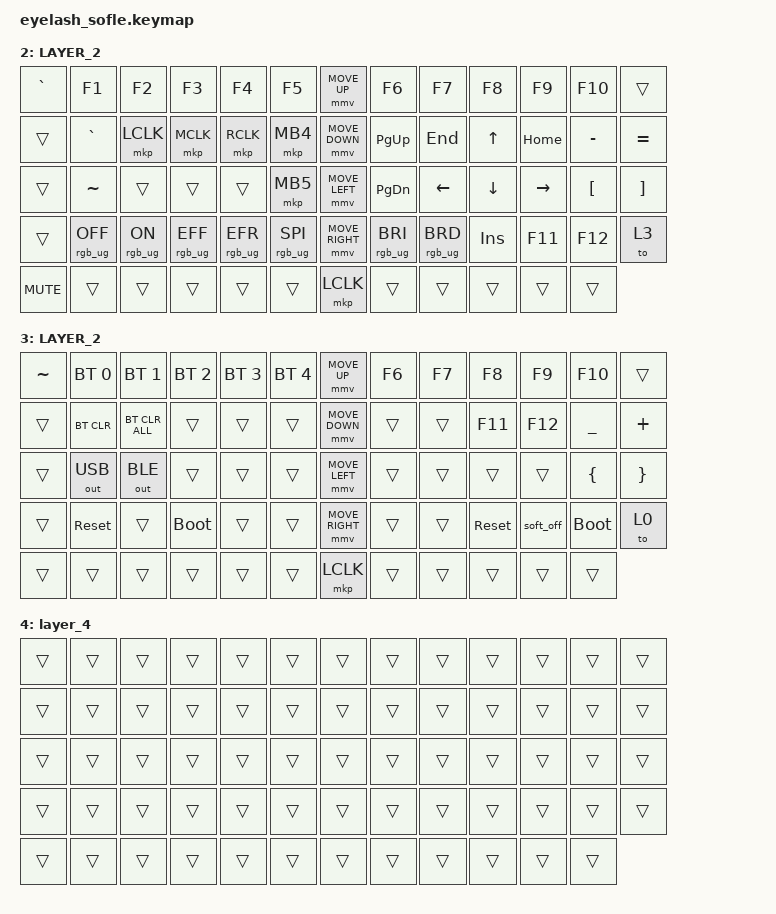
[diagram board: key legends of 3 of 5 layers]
#define ZMK_POINTING_DEFAULT_MOVE_VAL 1200  // 600
#define ZMK_POINTING_DEFAULT_SCRL_VAL 25   // 10

#include <input/processors.dtsi>
#include <zephyr/dt-bindings/input/input-event-codes.h>
#include <behaviors.dtsi>
#include <dt-bindings/zmk/bt.h>
#include <dt-bindings/zmk/ext_power.h>
#include <dt-bindings/zmk/keys.h>
#include <dt-bindings/zmk/pointing.h>
#include <dt-bindings/zmk/rgb.h>
#include <dt-bindings/zmk/outputs.h>

&mmv_input_listener { input-processors = <&zip_xy_scaler 2 1>; };

&msc_input_listener { input-processors = <&zip_scroll_scaler 2 1>; };

&msc {
    acceleration-exponent = <1>;      // 0
    time-to-max-speed-ms = <100>;       // 300
    delay-ms = <0>;                   // 0
};

&mmv {
    time-to-max-speed-ms = <500>;
    acceleration-exponent = <1>;
    trigger-period-ms = <16>;
};


/ {

    scroll_encoder: scroll_encoder {
        compatible = "zmk,behavior-sensor-rotate";
        #sensor-binding-cells = <0>;
        bindings = <&msc SCRL_DOWN>, <&msc SCRL_UP>;
        tap-ms = <100>;
    };

    keymap {
        compatible = "zmk,keymap";

        layer0 {
            bindings = <
&kp ESC	&kp N1	&kp N2	&kp N3	&kp N4	&kp N5	&kp UP_ARROW	&kp N6	&kp N7	&kp N8	&kp N9	&kp N0	&kp BACKSPACE
&kp TAB	&kp APOS	&kp COMMA	&kp DOT	&kp P	&kp Y	&kp DOWN_ARROW	&kp F	&kp G	&kp C	&kp R	&kp L	&kp FSLH
&kp LSHFT	&kp A	&kp O	&kp E	&kp U	&kp I	&kp LEFT_ARROW	&kp D	&kp H	&kp T	&kp N	&kp S	&kp MINUS
&kp LCTRL	&kp SEMI	&kp Q	&kp J	&kp K	&kp X	&kp RIGHT_ARROW	&kp B	&kp M	&kp W	&kp V	&kp Z	&to 2
&kp C_MUTE	&kp LEFT_ALT	&kp DELETE	&kp HOME	&mo 1	&kp ENTER	&kp SPACE	&mo 1	&kp END	&kp LEFT_GUI	&kp RIGHT_ALT
			>;

			sensor-bindings = <&inc_dec_kp C_VOLUME_UP C_VOL_DN>;
			display-name = "LAYER0";
		};

		layer_1 {
			bindings = <
&kp ESC	&kp F1	&kp F2	&kp F3	&kp F4	&kp F5	&mmv MOVE_UP	&kp F6	&kp F7	&kp F8	&kp F9	&kp F10	&kp F11
&kp TAB	&kp APOS	&kp COMMA	&kp DOT	&kp P	&kp Y	&kp DOWN_ARROW	&kp F	&kp LEFT_PARENTHESIS	&kp RIGHT_PARENTHESIS	&kp LEFT_BRACKET	&kp RIGHT_BRACKET	&kp F12
&kp LSHFT	&kp LG(L)	&kp LC(C)	&kp LC(V)	&kp LG(LS(S))	&kp GRAVE	&kp LEFT_ARROW	&kp D	&kp LEFT_ARROW	&kp DOWN_ARROW	&kp UP_ARROW	&kp RIGHT_ARROW	&kp MINUS
&kp LCTRL	&kp SEMI	&kp Q	&kp J	&kp K	&kp PAGE_UP	&kp RIGHT_ARROW	&kp PAGE_DOWN	&kp EQUAL	&kp PLUS	&kp BSLH	&kp PIPE	&trans
&kp C_MUTE	&kp LEFT_ALT	&kp DELETE	&kp HOME	&mo 1	&kp ENTER	&kp SPACE	&mo 1	&kp END	&kp LEFT_GUI	&kp RIGHT_ALT
			>;

			sensor-bindings = <&inc_dec_kp C_VOLUME_UP C_VOL_DN>;
			display-name = "LAYER_1";
		};

		layer_2 {
			bindings = <
&kp GRAVE	&kp F1	&kp F2	&kp F3	&kp F4	&kp F5	&mmv MOVE_UP	&kp F6	&kp F7	&kp F8	&kp F9	&kp F10	&trans
&trans	&kp GRAVE	&mkp LCLK	&mkp MCLK	&mkp RCLK	&mkp MB4	&mmv MOVE_DOWN	&kp PG_UP	&kp END	&kp UP	&kp HOME	&kp MINUS	&kp EQUAL
&trans	&kp TILDE	&trans	&trans	&trans	&mkp MB5	&mmv MOVE_LEFT	&kp PG_DN	&kp LEFT	&kp DOWN	&kp RIGHT	&kp LEFT_BRACKET	&kp RIGHT_BRACKET
&trans	&rgb_ug RGB_OFF	&rgb_ug RGB_ON	&rgb_ug RGB_EFF	&rgb_ug RGB_EFR	&rgb_ug RGB_SPI	&mmv MOVE_RIGHT	&rgb_ug RGB_BRI	&rgb_ug RGB_BRD	&kp INSERT	&kp F11	&kp F12	&to 3
&kp C_MUTE	&trans	&trans	&trans	&trans	&trans	&mkp LCLK	&trans	&trans	&trans	&trans	&trans
			>;

			display-name = "LAYER_2";
			sensor-bindings = <&scroll_encoder>;
		};

		layer_3 {
			bindings = <
&kp TILDE	&bt BT_SEL 0	&bt BT_SEL 1	&bt BT_SEL 2	&bt BT_SEL 3	&bt BT_SEL 4	&mmv MOVE_UP	&kp F6	&kp F7	&kp F8	&kp F9	&kp F10	&trans
&trans	&bt BT_CLR	&bt BT_CLR_ALL	&trans	&trans	&trans	&mmv MOVE_DOWN	&trans	&trans	&kp F11	&kp F12	&kp UNDER	&kp PLUS
&trans	&out OUT_USB	&out OUT_BLE	&trans	&trans	&trans	&mmv MOVE_LEFT	&trans	&trans	&trans	&trans	&kp LBRC	&kp RBRC
&trans	&sys_reset	&trans	&bootloader	&trans	&trans	&mmv MOVE_RIGHT	&trans	&trans	&sys_reset	&soft_off	&bootloader	&to 0
&trans	&trans	&trans	&trans	&trans	&trans	&mkp LCLK	&trans	&trans	&trans	&trans	&trans
	>;

			display-name = "LAYER_2";
			sensor-bindings = <&scroll_encoder>;
		};

		layer_4 {
			bindings = <
&trans	&trans	&trans	&trans	&trans	&trans	&trans	&trans	&trans	&trans	&trans	&trans	&trans
&trans	&trans	&trans	&trans	&trans	&trans	&trans	&trans	&trans	&trans	&trans	&trans	&trans
&trans	&trans	&trans	&trans	&trans	&trans	&trans	&trans	&trans	&trans	&trans	&trans	&trans
&trans	&trans	&trans	&trans	&trans	&trans	&trans	&trans	&trans	&trans	&trans	&trans	&trans
&trans	&trans	&trans	&trans	&trans	&trans	&trans	&trans	&trans	&trans	&trans	&trans
			>;
		};
	};
};
